# STM32MP23_CM33 register map
File version: 1.2
CPU: CM33 r0p1, little endian, MPU, FPU, vendor SysTick, 8 interrupt priority bits
Registers are 32-bit, read-write, reset 0x0 unless marked. A register's access mark holds for its fields unless they carry their own. Offsets are from the block's base; [hi:lo] are bit positions; {n}, {i} and the like mark numbered series; 'fields as' and 'values as' point back to an identical list.

## OTFDEC1 — OTFDEC register bank
Base 0x40450000
Same registers: OTFDEC2 0x40460000, OTFDEC1_S 0x50450000, OTFDEC2_S 0x50460000
0x00 OTFDEC_CR — OTFDEC control register
  [0] ENC — Encryption mode bit When this bit is set, OTFDEC is used in encryption mode, during which application can write clear text data then read back encrypted data. When this bit is cleared (default), OTFDEC is used in decryption mode, during which application only read back decrypted data. For both modes, cryptographic context (keys, nonces, firmware versions) must be properly initialized. When this bit is set, only data accesses are allowed (zeros are returned otherwise, and XONEIF is set). When MODE=11, enhanced encryption mode is automatically selected. Note: When ENC bit is set, no access to OCTOSPI must be done (registers and Memory-mapped region).
    0=OTFDEC working in decryption mode; 1=OTFDEC working in encryption mode
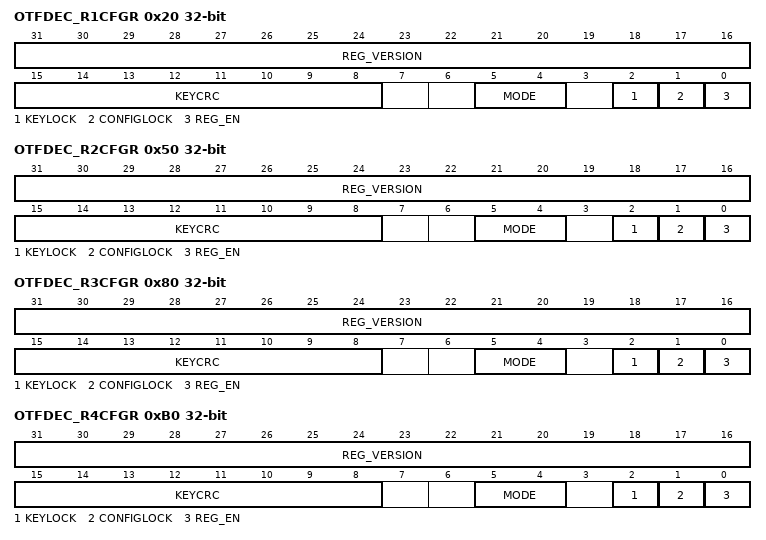
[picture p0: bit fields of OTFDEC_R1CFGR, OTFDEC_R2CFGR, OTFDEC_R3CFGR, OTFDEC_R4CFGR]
0x20 OTFDEC_R1CFGR — OTFDEC region 1 configuration register
  [31:16] REG_VERSION — region firmware version This 16-bit bit field must be correctly initialized before the region corresponding REG_EN bit is set in OTFDEC_RxCFGR.
  [15:8] KEYCRC ro — region key 8-bit CRC When KEYLOCK=0, KEYCRC bit field is automatically computed by hardware while loading the key of this region in this exact sequence: KEYR0 then KEYR1 then KEYR2 then finally KEYR3 (all written once). A new computation starts as soon as a new valid sequence is initiated, and KEYCRC is read as zero until a valid sequence is completed. When KEYLOCK=1, KEYCRC remains unchanged until the next reset. CRC computation is an 8-bit checksum using the standard CRC-8-CCITT algorithm Xsup8/sup + Xsup2/sup + X + 1 (according the convention). Source code is available in Section61.5.4. This field is read only. Note: CRC information is updated only after the last bit of the key has been written.
  [5:4] MODE — operating mode This bit field selects the OTFDEC operating mode for this region: Others: Reserved When MODE different 11, the standard AES encryption mode is activated. When either of the MODE bits are changed, the region key and associated CRC are zeroed.
    2=All read accesses are decrypted (instruction or data); 3=Enhanced encryption mode is activated, and only instruction accesses are decrypted
  [2] KEYLOCK — region key lock Note: This bit is set once: if this bit is set, it can only be reset to 0 if the OTFDEC is reset.
    0=Writes to this region KEYRx registers are allowed; 1=Writes to this region KEYRx registers are ignored until next OTFDEC reset. KEYCRC bit field is locked.
  [1] CONFIGLOCK — region config lock Note: This bit is set once. If this bit is set, it can only be reset to 0 if OTFDEC is reset. Setting this bit forces KEYLOCK bit to 1.
    0=Writes to this region OTFDEC_RxCFGR, OTFDEC_RxSTARTADDR, OTFDEC_RxENDADDR and OTFDEC_RxNONCERy registers are allowed; 1=Writes to this region OTFDEC_RxCFGR, OTFDEC_RxSTARTADDR, OTFDEC_RxENDADDR and OTFDEC_RxNONCERy registers are ignored until next OTFDEC reset
  [0] REG_EN — region on-the-fly decryption enable Note: Garbage is decrypted if region context (version, key, nonce) is not valid when this bitisset.
    0=On-the-fly decryption is disabled for this region; 1=On-the-fly decryption is enabled for this region. Data are XORed with the corresponding keystream.
0x24 OTFDEC_R1STARTADDR — OTFDEC region 1 start address register
  [31:0] REG_START_ADDR — Region AHB start address This register must be written before the region corresponding REG_EN bit in the OTFDEC_RxCFGR register is set. Writing to this register is discarded if performed while the region CONFIGLOCK bit in the OTFDEC_RxCFGR register is set. Note: When determining the region the first 12 bits (lsb) and the last 4 bits (msb) are ignored. When this register is accessed in read the 4 msb bits and the 12 lsb bits return zeros.
0x28 OTFDEC_R1ENDADDR reset 0xFFF — OTFDEC region 1 end address register
  [31:0] REG_END_ADDR — Region AHB end address This register must be written before the region corresponding REG_EN bit in the OTFDEC_RxCFGR register is set, and OTFDEC_RxENDADDR must be strictly greater than OTFDEC_RxSTARTADDR to be valid. Writing to this register is discarded if performed while the region CONFIGLOCK bit in OTFDEC_RxCFGR is set. Note: When determining the region the first 12 bits (lsb) and the last 4 bits (msb) are ignored. When this register is accessed in read the 4 msb bits return zeros and the 12 lsb bits return ones.
0x2C OTFDEC_R1NONCER0 — OTFDEC region 1 nonce register 0
  [31:0] REG_NONCE — Region nonce, bits [31:0] This register must be written before the region corresponding REG_EN bit in OTFDEC_RxCFGR is set. Writing is discarded in this register if performed while the region CONFIGLOCK bit in the OTFDEC_RxCFGR is set.
{0x0+0x30*i} OTFDEC_R{i}NONCER1 (i=1..4) — OTFDEC region {i} nonce register 1
  [31:0] REG_NONCE — Region nonce, bits [63:32] Refer to the OTFDEC_RxNONCER0 register for description of the NONCE[63:0] bit field.
{0x4+0x30*i} OTFDEC_R{i}KEYR0 wo (i=1..4) — OTFDEC region {i} key register 0
  [31:0] REG_KEY — Region key, bits [31:0] This register must be written before the region corresponding REG_EN bit in OTFDEC_RxCFGRisset. Reading this register returns a zero value. Writing to this register is discarded if performed while the region CONFIGLOCK or KEYLOCK bit is set in the OTFDEC_RxCFGR. Note: When application successfully changes MODE bits in OTFDEC_RxCFGR and OTFDEC_RxKEYR, and associated KEYCRC are erased.
{0x8+0x30*i} OTFDEC_R{i}KEYR1 wo (i=1..4) — OTFDEC region {i} key register 1
  [31:0] REG_KEY — Region key, bits [63:32] Refer to the OTFDEC_RxKEYR0 register for description of the KEY[127:0] bit field.
{0xC+0x30*i} OTFDEC_R{i}KEYR2 wo (i=1..4) — OTFDEC region {i} key register 2
  [31:0] REG_KEY — Region key, bits [95:64] Refer to the OTFDEC_RxKEYR0 register for description of the KEY[127:0] bit field.
{0x10+0x30*i} OTFDEC_R{i}KEYR3 wo (i=1..4) — OTFDEC region {i} key register 3
  [31:0] REG_KEY — Region key, bits [127:96] Refer to the OTFDEC_RxKEYR0 register for description of the KEY[127:0] bit field.
0x50 OTFDEC_R2CFGR — OTFDEC region 2 configuration register
  fields as OTFDEC_R1CFGR
0x54 OTFDEC_R2STARTADDR — OTFDEC region 2 start address register
  fields as OTFDEC_R1STARTADDR
0x58 OTFDEC_R2ENDADDR reset 0xFFF — OTFDEC region 2 end address register
  fields as OTFDEC_R1ENDADDR
0x5C OTFDEC_R2NONCER0 — OTFDEC region 2 nonce register 0
  fields as OTFDEC_R1NONCER0
0x80 OTFDEC_R3CFGR — OTFDEC region 3 configuration register
  fields as OTFDEC_R1CFGR
0x84 OTFDEC_R3STARTADDR — OTFDEC region 3 start address register
  fields as OTFDEC_R1STARTADDR
0x88 OTFDEC_R3ENDADDR reset 0xFFF — OTFDEC region 3 end address register
  fields as OTFDEC_R1ENDADDR
0x8C OTFDEC_R3NONCER0 — OTFDEC region 3 nonce register 0
  fields as OTFDEC_R1NONCER0
0xB0 OTFDEC_R4CFGR — OTFDEC region 4 configuration register
  fields as OTFDEC_R1CFGR
0xB4 OTFDEC_R4STARTADDR — OTFDEC region 4 start address register
  fields as OTFDEC_R1STARTADDR
0xB8 OTFDEC_R4ENDADDR reset 0xFFF — OTFDEC region 4 end address register
  fields as OTFDEC_R1ENDADDR
0xBC OTFDEC_R4NONCER0 — OTFDEC region 4 nonce register 0
  fields as OTFDEC_R1NONCER0
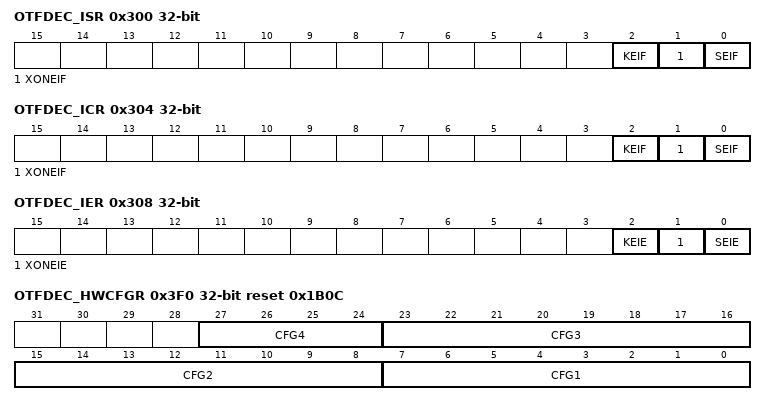
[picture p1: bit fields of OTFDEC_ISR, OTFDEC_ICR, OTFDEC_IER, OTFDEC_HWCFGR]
0x300 OTFDEC_ISR ro — OTFDEC interrupt status register
  [2] KEIF — Key error interrupt flag status This bit is set by hardware and read only by application. The bit is set when a read access occurs on an encrypted region, while its key registers is null or not properly initialized (KEYCRC=0x0). This bit is cleared when the application sets in OTFDEC_ICR the corresponding bit to 1. After KEIF is set any subsequent read to the region with bad key registers returns a zeroed value. This state remains until those key registers are properly initialized (KEYCRC not zero).
    0=OTFDEC operates properly; 1=Read access detected on an enabled encrypted region with its key registers null or not properly initialized (KEYCRC=0x0). OTFDEC returns a zeroed value for the read, and an optional interrupt is generated if bit KEIE is set to 1 in OTFDEC_IER.
  [1] XONEIF — Execute-only execute-never error interrupt flag status This bit is set by hardware and read only by application. This bit is set when a read access and not an instruction fetch is detected on any encrypted region with MODE bits set to 11. Lastly, XONEIF is also set when an execute access is detected while encryption mode is enabled. This bit is cleared when application sets in OTFDEC_ICR the corresponding bit to 1.
    0=No execute-only error status. No interrupt pending.; 1=Read access detected on one region with MODE bits set to 11 or execute access detected while ENC=1. OTFDEC returns a zeroed value for the illegal access, and an optional interrupt is generated if bit XONEIE is set to 1 in OTFDEC_IER.
  [0] SEIF — Security error interrupt flag status This bit is set by hardware and read only by application. This bit is set when at least one security error has been detected. This bit is cleared when application sets in OTFDEC_ICR the corresponding bit to 1.
    0=No security error status. No interrupt pending.; 1=Security error flag status, with interrupt pending. Actual interrupt generation is dependent on OTFDEC_IER corresponding bit SEIE.
0x304 OTFDEC_ICR wo — OTFDEC interrupt clear register
  [2] KEIF — Key error interrupt flag clear This bit is written by application, and always read as 0. Note: Clearing KEIF does not solve the source of the problem (bad key registers). To be able to access again any encrypted region, OTFDEC key registers must be properly initialized again.
    0=KEIF flag status is not affected; 1=KEIF flag status is cleared in OTFDEC_ISR
  [1] XONEIF — Execute-only execute-never error interrupt flag clear This bit is written by application, and always read as 0.
    0=XONEIF flag status is not affected; 1=XONEIF flag status is cleared in OTFDEC_ISR
  [0] SEIF — Security error interrupt flag clear This bit is written by application, and always read as 0.
    0=SEIF flag status is not affected; 1=SEIF flag status is cleared in OTFDEC_ISR
0x308 OTFDEC_IER — OTFDEC interrupt enable register
  [2] KEIE — Key error interrupt enable This bit is read and written by application. It controls the OTFDEC interrupt generation when KEIF flag status is set.
    0=Interrupt generation on key error flag KEIF is disabled (masked); 1=Interrupt generation on key error flag KEIF is enabled (not masked)
  [1] XONEIE — Execute-only execute-never error interrupt enable This bit is read and written by application. It controls the OTFDEC interrupt generation when XONEIF flag status is set.
    0=Interrupt generation on execute-only error XONEIF is disabled (masked); 1=Interrupt generation on execute-only error XONEIF is enabled (not masked)
  [0] SEIE — Security error interrupt enable This bit is read and written by application. It controls the OTFDEC interrupt generation when SEIF flag status is set.
    0=Interrupt generation on security error SEIF is disabled (masked); 1=Interrupt generation on security error SEIF is enabled (not masked)
0x3F0 OTFDEC_HWCFGR ro reset 0x1B0C — OTFDEC hardware configuration register
  [27:24] CFG4 — Hardware Generic 4 This field returns the low_clk_freq generic value (0x00).
  [23:16] CFG3 — Hardware Generic 3 This field returns the option_bits generic value (0x00).
  [15:8] CFG2 — Hardware Generic 2 This field returns the address_region_msb generic value (0x1B).
  [7:0] CFG1 — Hardware Generic 1 This field returns the address_region_lsb generic value (0x0C).
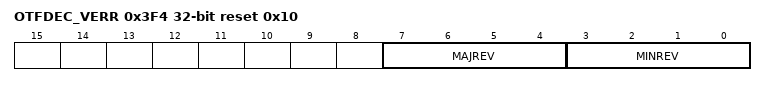
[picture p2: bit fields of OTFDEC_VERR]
0x3F4 OTFDEC_VERR ro reset 0x10 — OTFDEC version register
  [7:4] MAJREV — Major revision This field returns the OTFDEC peripheral major version.
  [3:0] MINREV — Minor revision This field returns the OTFDEC peripheral minor version.
0x3F8 OTFDEC_IPIDR ro reset 0x170051 — OTFDEC identification register
  [31:0] ID — Identification code This field returns the identification code of the OTFDEC (AHB) peripheral.
0x3FC OTFDEC_SIDR ro reset 0xA3C5DD01 — OTFDEC size identification register
  [31:0] SID — Size identification code This field returns the size identification code of the OTFDEC peripheral as defined below: Bits[31:8] = 0xA3C5DD (fixed code) Bits[7:0] = 0x01 (1KB address decoding)
